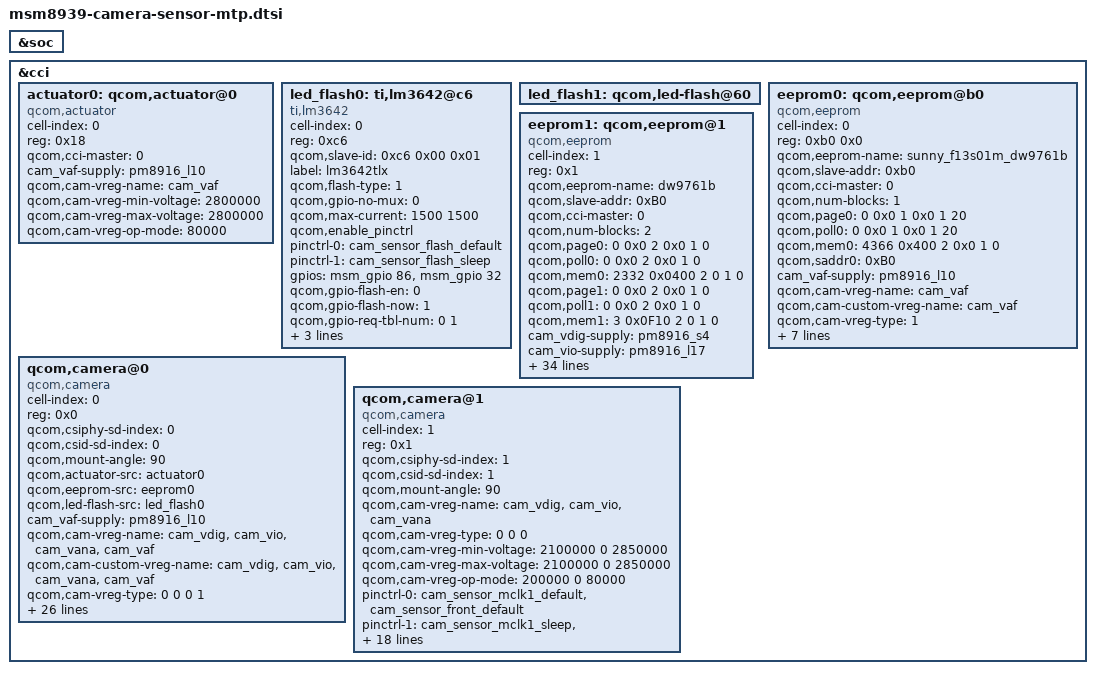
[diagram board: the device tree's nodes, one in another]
/*
 * Copyright (c) 2014-2015, The Linux Foundation. All rights reserved.
 *
 * This program is free software; you can redistribute it and/or modify
 * it under the terms of the GNU General Public License version 2 and
 * only version 2 as published by the Free Software Foundation.
 *
 * This program is distributed in the hope that it will be useful,
 * but WITHOUT ANY WARRANTY; without even the implied warranty of
 * MERCHANTABILITY or FITNESS FOR A PARTICULAR PURPOSE.  See the
 * GNU General Public License for more details.
 */

/*lenovo-sw chenglong1 modify start*/
/*Whole file for Passion camera driver*/

&soc {
};

&cci {

	actuator0: qcom,actuator@0 {
		cell-index = <0>;
		reg = <0x18>;
		compatible = "qcom,actuator";
		qcom,cci-master = <0>;
		cam_vaf-supply = <&pm8916_l10>;
		qcom,cam-vreg-name = "cam_vaf";
		qcom,cam-vreg-min-voltage = <2800000>;
		qcom,cam-vreg-max-voltage = <2800000>;
		qcom,cam-vreg-op-mode = <80000>;
	};

	led_flash0: ti,lm3642@c6 {
		cell-index = <0>;
		reg = <0xc6>;
		qcom,slave-id = <0xc6 0x00 0x01>;
		compatible = "ti,lm3642";
		label = "lm3642tlx";
		qcom,flash-type = <1>;
		qcom,gpio-no-mux = <0>;
		qcom,max-current = <1500 1500>;
		qcom,enable_pinctrl;
		pinctrl-names = "cam_flash_default", "cam_flash_suspend";
		pinctrl-0 = <&cam_sensor_flash_default>;
		pinctrl-1 = <&cam_sensor_flash_sleep>;
		gpios = <&msm_gpio 86 0>,
			<&msm_gpio 32 0>;
		qcom,gpio-flash-en = <0>;
		qcom,gpio-flash-now = <1>;
		qcom,gpio-req-tbl-num = <0 1>;
		qcom,gpio-req-tbl-flags = <0 0>;
		qcom,gpio-req-tbl-label = "FLASH_EN",
			"FLASH_NOW";
		qcom,cci-master = <0>;
	};

	led_flash1: qcom,led-flash@60 {
		/*cell-index = <1>;
		reg = <0x60>;
		qcom,slave-id = <0x60 0x00 0x0011>;
		compatible = "qcom,led-flash";
		label = "adp1660";
		qcom,flash-type = <1>;
		qcom,gpio-no-mux = <0>;
		qcom,enable_pinctrl;
		pinctrl-names = "cam_flash_default", "cam_flash_suspend";
		pinctrl-0 = <&cam_sensor_flash_default>;
		pinctrl-1 = <&cam_sensor_flash_sleep>;
		gpios = <&msm_gpio 36 0>,
				<&msm_gpio 32 0>,
				<&msm_gpio 31 0>;
		qcom,gpio-flash-reset = <0>;
		qcom,gpio-flash-en = <1>;
		qcom,gpio-flash-now = <2>;
		qcom,gpio-req-tbl-num = <0 1 2>;
		qcom,gpio-req-tbl-flags = <0 0 0>;
		qcom,gpio-req-tbl-label = "FLASH_RST",
				"FLASH_EN",
				"FLASH_NOW";
		qcom,cci-master = <0>;*/
	};
	
	eeprom0: qcom,eeprom@b0 {
		cell-index = <0>;
		reg = <0xb0 0x0>;
		qcom,eeprom-name = "sunny_f13s01m_dw9761b";
		compatible = "qcom,eeprom";
		qcom,slave-addr = <0xb0>;
		qcom,cci-master = <0>;
		qcom,num-blocks = <1>;

		qcom,page0 = <0 0x0 1 0x0 1 20>;
		qcom,poll0 = <0 0x0 1 0x0 1 20>;
		qcom,mem0 = <4366 0x400 2 0x0 1 0>;
		qcom,saddr0 = <0xB0>;

		cam_vaf-supply = <&pm8916_l10>;
		qcom,cam-vreg-name = "cam_vaf";
		qcom,cam-custom-vreg-name = "cam_vaf";
		qcom,cam-vreg-type = <1>;
		qcom,cam-vreg-min-voltage = <2800000>;
		qcom,cam-vreg-max-voltage = <2800000>;
		qcom,cam-vreg-op-mode = <100000>;
		/*
		gpios = <&msm_gpio 26 0>, //MCLk
			<&msm_gpio 35 0>, //RST
			<&msm_gpio 34 0>, //PWDWN
			<&msm_gpio 11 0>; //DVDD
		qcom,gpio-reset = <1>;
		qcom,gpio-standby =<2>;
		qcom,gpio-vdig =<3>;
		qcom,gpio-req-tbl-num = <0 1 2 3>;
		qcom,gpio-req-tbl-flags = <1 0 0 0>;
		qcom,gpio-req-tbl-label = "CAMIF_MCLK",
			"CAM_RESET1",
	        "CAM_PWDWN1",
	        "CAM_VDIG";*/

		//qcom,cam-power-seq-type = "sensor_gpio", "sensor_gpio", "sensor_gpio";
		//qcom,cam-power-seq-val = "sensor_gpio_vdig", "sensor_gpio_vio", "sensor_gpio_vana";
		qcom,cam-power-seq-type = "sensor_vreg";
		qcom,cam-power-seq-val = "cam_vaf";
		qcom,cam-power-seq-cfg-val = <1>;
		qcom,cam-power-seq-delay = <1>;
	};

	eeprom1: qcom,eeprom@1 {
		cell-index = <1>;
		reg = <0x1>;
		qcom,eeprom-name = "dw9761b";
		compatible = "qcom,eeprom";
		qcom,slave-addr = <0xB0>;
		qcom,cci-master = <0>;
		qcom,num-blocks = <2>;
		qcom,page0 = <0 0x0 2 0x0 1 0>;
		qcom,poll0 = <0 0x0 2 0x0 1 0>;
		qcom,mem0 = <2332 0x0400 2 0 1 0>;

		qcom,page1 = <0 0x0 2 0x0 1 0>;
		qcom,poll1 = <0 0x0 2 0x0 1 0>;
		qcom,mem1 = <3 0x0F10 2 0 1 0>;

		cam_vdig-supply = <&pm8916_s4>;
		cam_vio-supply = <&pm8916_l17>;
		cam_vana-supply = <&pm8916_l6>;
		cam_vaf-supply = <&pm8916_l10>;
		qcom,cam-vreg-name = "cam_vdig", "cam_vio", "cam_vana", "cam_vaf";
		qcom,cam-vreg-min-voltage = <2100000 0 1800000 2800000>;
		qcom,cam-vreg-max-voltage = <2100000 0 1800000 2800000>;
		qcom,cam-vreg-op-mode = <200000 0 80000 100000>;
		pinctrl-names = "cam_default", "cam_suspend";
		pinctrl-0 = <&cam_sensor_mclk0_default &cam_sensor_rear_default>;
		pinctrl-1 = <&cam_sensor_mclk0_sleep &cam_sensor_rear_sleep>;
		qcom,gpio-no-mux = <0>;
		gpios = <&msm_gpio 26 0>,
			<&msm_gpio 35 0>,
			<&msm_gpio 34 0>;
		qcom,gpio-reset = <1>;
		qcom,gpio-standby = <2>;
		qcom,gpio-req-tbl-num = <0 1 2>;
		qcom,gpio-req-tbl-flags = <1 0 0>;
		qcom,gpio-req-tbl-label = "CAMIF_MCLK0",
			"CAM_RESET0",
			"CAM_STANDBY0";
		qcom,gpio-set-tbl-num = <1 1>;
		qcom,gpio-set-tbl-flags = <0 2>;
		qcom,gpio-set-tbl-delay = <1000 4000>;

		qcom,cam-power-seq-type = "sensor_vreg", "sensor_vreg", "sensor_vreg",
			"sensor_vreg", "sensor_gpio", "sensor_clk";
		qcom,cam-power-seq-val = "cam_vdig", "cam_vana", "cam_vio", "cam_vaf",
			"sensor_gpio_reset", "sensor_cam_mclk";
		qcom,cam-power-seq-cfg-val = <1 1 1 1 1 24000000>;
		qcom,cam-power-seq-delay = <1 1 1 1 30 5>;
		clocks = <&clock_gcc clk_mclk0_clk_src>,
				<&clock_gcc clk_gcc_camss_mclk0_clk>;
		clock-names = "cam_src_clk", "cam_clk";
	};

	qcom,camera@0 {
		cell-index = <0>;
		compatible = "qcom,camera";
		reg = <0x0>;
		qcom,csiphy-sd-index = <0>;
		qcom,csid-sd-index = <0>;
		qcom,mount-angle = <90>;
		qcom,actuator-src = <&actuator0>;
		qcom,eeprom-src = <&eeprom0>;
		qcom,led-flash-src = <&led_flash0>;
		//cam_vdig-supply = <&pm8916_s4>;
		//cam_vana-supply = <&pm8916_l17>;
		//cam_vio-supply = <&pm8916_l6>;
		cam_vaf-supply = <&pm8916_l10>;
		qcom,cam-vreg-name = "cam_vdig", "cam_vio", "cam_vana",
							"cam_vaf";
		qcom,cam-custom-vreg-name = "cam_vdig", "cam_vio", "cam_vana",
							"cam_vaf";
		qcom,cam-vreg-type = <0 0 0 1>;
		qcom,cam-vreg-min-voltage = <2100000 0 2850000 2800000>;
		qcom,cam-vreg-max-voltage = <2100000 0 2850000 2800000>;
		qcom,cam-vreg-op-mode = <200000 0 80000 100000>;
		pinctrl-names = "cam_default", "cam_suspend";
		pinctrl-0 = <&cam_sensor_mclk0_default
				&cam_sensor_rear_default>;
		pinctrl-1 = <&cam_sensor_mclk0_sleep &cam_sensor_rear_sleep>;
		gpios = <&msm_gpio 26 0>,
			<&msm_gpio 35 0>,
			<&msm_gpio 28 0>,
			<&msm_gpio 17 0>,
			<&msm_gpio 16 0>,
			<&msm_gpio 77 0>;
		qcom,gpio-reset = <1>;
		qcom,gpio-standby = <2>;
		qcom,gpio-vana = <3>;
		qcom,gpio-vio = <4>;
		qcom,gpio-vdig = <5>;
		qcom,gpio-req-tbl-num = <0 1 2 3 4 5>;
		qcom,gpio-req-tbl-flags = <1 0 0 0 0 0>;
		qcom,gpio-req-tbl-label = "CAMIF_MCLK0",
			"CAM_RESET0",
			"CAM_STANDBY0",
			"CAM_VANA",
			"CAM_VIO",
			"CAM_VDIG";
		qcom,sensor-position = <0>;
		qcom,sensor-mode = <0>;
		qcom,cci-master = <0>;
		status = "ok";
		clocks = <&clock_gcc clk_mclk0_clk_src>,
				<&clock_gcc clk_gcc_camss_mclk0_clk>;
		clock-names = "cam_src_clk", "cam_clk";
	};

	qcom,camera@1 {
		cell-index = <1>;
		compatible = "qcom,camera";
		reg = <0x1>;
		qcom,csiphy-sd-index = <1>;
		qcom,csid-sd-index = <1>;
		qcom,mount-angle = <90>;
		//qcom,led-flash-src = <&led_flash0>;
		//cam_vdig-supply = <&pm8916_s4>;
		//cam_vana-supply = <&pm8916_l17>;
		//cam_vio-supply = <&pm8916_l6>;
		qcom,cam-vreg-name = "cam_vdig", "cam_vio", "cam_vana";
		qcom,cam-vreg-type = <0 0 0>;
		qcom,cam-vreg-min-voltage = <2100000 0 2850000>;
		qcom,cam-vreg-max-voltage = <2100000 0 2850000>;
		qcom,cam-vreg-op-mode = <200000 0 80000>;
		pinctrl-names = "cam_default", "cam_suspend";
		pinctrl-0 = <&cam_sensor_mclk1_default &cam_sensor_front_default>;
		pinctrl-1 = <&cam_sensor_mclk1_sleep &cam_sensor_front_sleep>;
		gpios = <&msm_gpio 27 0>,
			<&msm_gpio 36 0>,
			<&msm_gpio 33 0>,
			<&msm_gpio 17 0>,
			<&msm_gpio 16 0>,
			<&msm_gpio 95 0>;
		qcom,gpio-reset = <1>;
		qcom,gpio-standby = <2>;
		qcom,gpio-vana = <3>;
		qcom,gpio-vio = <4>;
		qcom,gpio-vdig = <5>;
		qcom,gpio-req-tbl-num = <0 1 2 3 4 5>;
		qcom,gpio-req-tbl-flags = <1 0 0 0 0 0>;
		qcom,gpio-req-tbl-label = "CAMIF_MCLK1",
			"CAM_RESET1",
			"CAM_STANDBY1",
			"CAM_VANA",
			"CAM_VIO",
			"CAM_VDIG";
		qcom,sensor-position = <1>;
		qcom,sensor-mode = <0>;
		qcom,cci-master = <0>;
		status = "ok";
		clocks = <&clock_gcc clk_mclk1_clk_src>,
				<&clock_gcc clk_gcc_camss_mclk1_clk>;
		clock-names = "cam_src_clk", "cam_clk";
	};
};
/*lenovo-sw modify end*/
